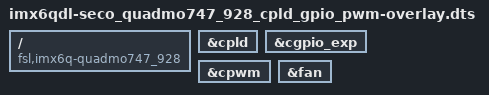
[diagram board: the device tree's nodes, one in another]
/dts-v1/;
/plugin/;

/ {
	compatible = "fsl,imx6q-quadmo747_928", "fsl,imx6dl-quadmo747_928", "fsl,imx6q", "fsl,imx6dl";

    fragment@0 {
   		target = <&cpld>;
        __overlay__ {

            status = "okay";

		};
	};


    fragment@1 {
   		target = <&cgpio_exp>;
        __overlay__ {

            status = "okay";

		};
	};

	
	fragment@2 {
   		target = <&cpwm>;
        __overlay__ {

            status = "okay";

		};
	};


	fragment@3 {
   		target = <&fan>;
         __overlay__ {

            status = "okay";

	 	};
	 };

};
